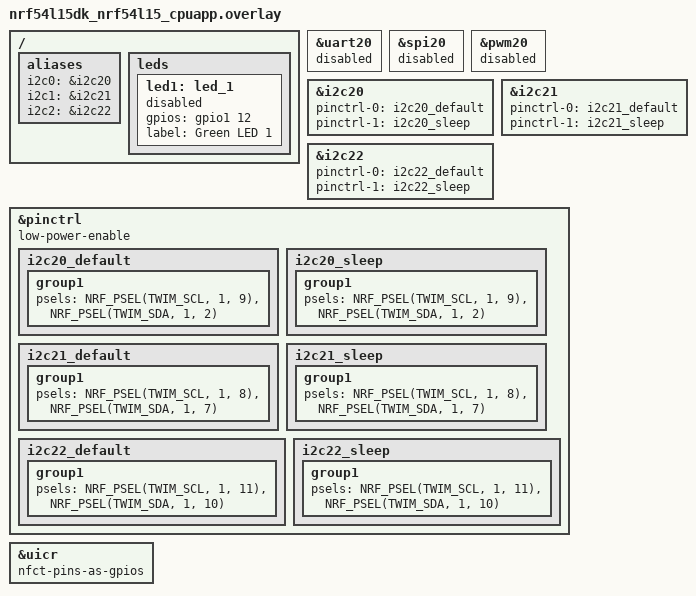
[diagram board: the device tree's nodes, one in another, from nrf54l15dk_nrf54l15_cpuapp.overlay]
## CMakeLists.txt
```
cmake_minimum_required(VERSION 3.20.0)
find_package(Zephyr REQUIRED HINTS $ENV{ZEPHYR_BASE})
project(Nadi_Pulse_AV)

target_sources(app PRIVATE src/main.c)
```

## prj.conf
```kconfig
CONFIG_BT=y
CONFIG_BT_PERIPHERAL=y
CONFIG_BT_DEVICE_NAME="NADI_PULSE_AV"
CONFIG_BT_GATT_CLIENT=y
CONFIG_BT_USER_DATA_LEN_UPDATE=y
CONFIG_BT_CTLR_DATA_LENGTH_MAX=251
CONFIG_BT_BUF_ACL_RX_SIZE=251
CONFIG_BT_BUF_ACL_TX_SIZE=251
CONFIG_BT_L2CAP_TX_MTU=247
CONFIG_BT_CTLR_PHY_2M=y
CONFIG_SYSTEM_WORKQUEUE_STACK_SIZE=2048
CONFIG_MAIN_STACK_SIZE=2048
CONFIG_BT_RX_STACK_SIZE=2048
CONFIG_LOG=y
CONFIG_SERIAL=y
CONFIG_PRINTK=y
CONFIG_I2C=y
CONFIG_SENSOR=y
CONFIG_NRF_FUEL_GAUGE=y
CONFIG_NRF_FUEL_GAUGE_VARIANT_SECONDARY_CELL=y
CONFIG_BT_DATA_LEN_UPDATE=y
CONFIG_BT_USER_PHY_UPDATE=y
CONFIG_BT_PHY_UPDATE=y
CONFIG_BT_AUTO_PHY_UPDATE=n
CONFIG_BT_BUF_CMD_TX_COUNT=10
CONFIG_BT_CTLR_PHY_CODED=y
CONFIG_MCUBOOT_IMGTOOL_SIGN_VERSION="0.1.0"
CONFIG_NCS_SAMPLE_MCUMGR_BT_OTA_DFU=y
```

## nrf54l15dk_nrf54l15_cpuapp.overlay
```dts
/ {
   aliases {
    i2c0 = &i2c20;
	i2c1 = &i2c21;
	i2c2 = &i2c22;
   };
   leds {
	led1: led_1 {
			status="disabled";
			gpios = <&gpio1 12 GPIO_ACTIVE_HIGH>;
			label = "Green LED 1";
		};
   };
};
&uart20 { status = "disabled"; };
&spi20 { status = "disabled"; };
&pwm20 {status="disabled";};
&i2c20 {
    status="okay";
    pinctrl-0 = <&i2c20_default>;
	pinctrl-1 = <&i2c20_sleep>;
	pinctrl-names = "default", "sleep";
};

&i2c21 {
    status="okay";
    pinctrl-0 = <&i2c21_default>;
	pinctrl-1 = <&i2c21_sleep>;
	pinctrl-names = "default", "sleep";
};

&i2c22 {
    status="okay";
    pinctrl-0 = <&i2c22_default>;
	pinctrl-1 = <&i2c22_sleep>;
	pinctrl-names = "default", "sleep";
};


&pinctrl {

	i2c20_default: i2c20_default {
		group1 {
			psels = <NRF_PSEL(TWIM_SCL, 1, 9)>, <NRF_PSEL(TWIM_SDA, 1, 2)>;
		};
	};

	i2c20_sleep: i2c20_sleep {
		group1 {
			psels = <NRF_PSEL(TWIM_SCL, 1, 9)>, <NRF_PSEL(TWIM_SDA, 1, 2)>;
		};
	};

	i2c21_default: i2c21_default {
		group1 {
			psels = <NRF_PSEL(TWIM_SCL, 1, 8)>, <NRF_PSEL(TWIM_SDA, 1, 7)>;
		};
	};

	i2c21_sleep: i2c21_sleep {
		group1 {
			psels = <NRF_PSEL(TWIM_SCL, 1, 8)>, <NRF_PSEL(TWIM_SDA, 1, 7)>;
		};
	};

	i2c22_default: i2c22_default {
		group1 {
			psels = <NRF_PSEL(TWIM_SCL, 1, 11)>, <NRF_PSEL(TWIM_SDA, 1, 10)>;
		};
	};

	i2c22_sleep: i2c22_sleep {
		group1 {
			psels = <NRF_PSEL(TWIM_SCL, 1, 11)>, <NRF_PSEL(TWIM_SDA, 1, 10)>;
		};
	};

	low-power-enable;
	
};

&uicr {
	nfct-pins-as-gpios;
};
```

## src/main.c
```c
#include <zephyr/kernel.h>
#include <zephyr/device.h>
#include <zephyr/drivers/i2c.h>
#include <zephyr/bluetooth/bluetooth.h>
#include "fuel_gauge.h"
#include "ble.h"

// MAX30102 Register map
#define I2C_DEV_LABEL0 DT_ALIAS(i2c0)
#define I2C_DEV_LABEL1 DT_ALIAS(i2c1)
#define I2C_DEV_LABEL2 DT_ALIAS(i2c2)
#define MAX30102_I2C_ADDR 0x57
#define REG_INTR_STATUS_1 0x00
#define REG_INTR_ENABLE_1 0x02
#define REG_FIFO_WR_PTR 0x04
#define REG_OVF_COUNTER 0x05
#define REG_FIFO_RD_PTR 0x06
#define REG_FIFO_DATA 0x07
#define REG_FIFO_CONFIG 0x08
#define REG_MODE_CONFIG 0x09
#define REG_SPO2_CONFIG 0x0A
#define REG_LED1_PA 0x0C
#define REG_LED2_PA 0x0D


const struct device *i2c_dev0, *i2c_dev1, *i2c_dev2;
/* Nadi pulse Data */
uint8_t x;
uint8_t y = 0;
uint32_t red0, ir0;
uint32_t red1, ir1;
uint32_t red2, ir2;
int32_t sub_red_0 = 0, sub_ir_0 = 0;
int32_t sub_red_1 = 0, sub_ir_1 = 0;
int32_t sub_red_2 = 0, sub_ir_2 = 0;
int32_t prev_red_0 = 0, prev_ir_0 = 0;
int32_t prev_red_1 = 0, prev_ir_1 = 0;
int32_t prev_red_2 = 0, prev_ir_2 = 0;

static int write_reg0(uint8_t reg, uint8_t value)
{
    uint8_t buf[2] = {reg, value};
    return i2c_write(i2c_dev0, buf, sizeof(buf), MAX30102_I2C_ADDR);
}
static int read_reg0(uint8_t reg, uint8_t *value)
{
    return i2c_write_read(i2c_dev0, MAX30102_I2C_ADDR, &reg, 1, value, 1);
}

static int read_fifo0(uint32_t *red, uint32_t *ir)
{
    uint8_t reg = REG_FIFO_DATA;
    uint8_t data[6];

    i2c_write_read(i2c_dev0, MAX30102_I2C_ADDR, &reg, 1, data, 6);
    red0 = ((uint32_t)data[0] << 16) |
           ((uint32_t)data[1] << 8) |
           data[2];
    ir0 = ((uint32_t)data[3] << 16) |
          ((uint32_t)data[4] << 8) | data[5];

    sub_red_0 = (red0 - prev_red_0);
    sub_ir_0 = (ir0 - prev_ir_0);

    if (sub_red_0 > 1000)
    {
        sub_red_0 = 1000;
    }
    else if (sub_red_0 < -1000)
    {
        sub_red_0 = -1000;
    }
    if (sub_ir_0 > 1000)
    {
        sub_ir_0 = 1000;
    }
    else if (sub_ir_0 < -1000)
    {
        sub_ir_0 = -1000;
    }
    prev_red_0 = red0;
    prev_ir_0 = ir0;
    return 0;
}

static int write_reg1(uint8_t reg, uint8_t value)
{
    uint8_t buf[2] = {reg, value};
    return i2c_write(i2c_dev1, buf, sizeof(buf), MAX30102_I2C_ADDR);
}
static int read_reg1(uint8_t reg, uint8_t *value)
{
    return i2c_write_read(i2c_dev1, MAX30102_I2C_ADDR, &reg, 1, value, 1);
}

// Read 6 bytes from FIFO (3 for RED, 3 for IR)
static int read_fifo1(uint32_t *red, uint32_t *ir)
{
    uint8_t reg = REG_FIFO_DATA;
    uint8_t data[6];

    i2c_write_read(i2c_dev1, MAX30102_I2C_ADDR, &reg, 1, data, 6);
    red1 = ((uint32_t)data[0] << 16) |
           ((uint32_t)data[1] << 8) |
           data[2];
    ir1 = ((uint32_t)data[3] << 16) |
          ((uint32_t)data[4] << 8) |
          data[5];

    sub_red_1 = (red1 - prev_red_1);
    sub_ir_1 = (ir1 - prev_ir_1);

    if (sub_red_1 > 1000)
    {
        sub_red_1 = 1000;
    }
    else if (sub_red_1 < -1000)
    {
        sub_red_1 = -1000;
    }
    if (sub_ir_1 > 1000)
    {
        sub_ir_1 = 1000;
    }
    else if (sub_ir_1 < -1000)
    {
        sub_ir_1 = -1000;
    }
    prev_red_1 = red1;
    prev_ir_1 = ir1;
    return 0;
}

static int write_reg2(uint8_t reg, uint8_t value)
{
    uint8_t buf[2] = {reg, value};
    return i2c_write(i2c_dev2, buf, sizeof(buf), MAX30102_I2C_ADDR);
}

static int read_reg2(uint8_t reg, uint8_t *value)
{
    return i2c_write_read(i2c_dev2, MAX30102_I2C_ADDR, &reg, 1, value, 1);
}

static int read_fifo2(uint32_t *red, uint32_t *ir)
{
    uint8_t reg = REG_FIFO_DATA;
    uint8_t data[6];

    i2c_write_read(i2c_dev2, MAX30102_I2C_ADDR, &reg, 1, data, 6);
    red2 = ((uint32_t)data[0] << 16) |
           ((uint32_t)data[1] << 8) |
           data[2];
    ir2 = ((uint32_t)data[3] << 16) |
          ((uint32_t)data[4] << 8) |
          data[5];

    sub_red_2 = (red2 - prev_red_2);
    sub_ir_2 = (ir2 - prev_ir_2);

    if (sub_red_2 > 1000)
    {
        sub_red_2 = 1000;
    }
    else if (sub_red_2 < -1000)
    {
        sub_red_2 = -1000;
    }
    if (sub_ir_2 > 1000)
    {
        sub_ir_2 = 1000;
    }
    else if (sub_ir_2 < -1000)
    {
        sub_ir_2 = -1000;
    }

    prev_red_2 = red2;
    prev_ir_2 = ir2;

    return 0;
}

static void max30102_init0(void)
{
    write_reg0(REG_MODE_CONFIG, 0x40);
    k_msleep(100);
    write_reg0(REG_FIFO_WR_PTR, 0x00);
    write_reg0(REG_OVF_COUNTER, 0x00);
    write_reg0(REG_FIFO_RD_PTR, 0x00);
    write_reg0(REG_FIFO_CONFIG, 0x4F);
    write_reg0(REG_MODE_CONFIG, 0x03);
   /*
    [7:5] = 0b100 = 400 Hz
    [4:2] = 0b01  = 118 us pulse
    [1:0] = 0b11  = 18-bit ADC*/
    write_reg0(REG_SPO2_CONFIG, 0x3b);
    write_reg0(REG_LED2_PA, 0x3f);
    write_reg0(REG_LED1_PA, 0x4f);
    write_reg0(0x11, 0x21);
    write_reg0(0x12, 0x00);
    printk("MAX30102_0 initialized");
}

static void max30102_init1(void)
{
    write_reg1(REG_MODE_CONFIG, 0x40);
    k_msleep(100);
    write_reg1(REG_FIFO_WR_PTR, 0x00);
    write_reg1(REG_OVF_COUNTER, 0x00);
    write_reg1(REG_FIFO_RD_PTR, 0x00);
    write_reg1(REG_FIFO_CONFIG, 0x4F);
    write_reg1(REG_MODE_CONFIG, 0x03);
    write_reg1(REG_SPO2_CONFIG, 0x3b);
    write_reg1(REG_LED2_PA, 0x3f);
    write_reg1(REG_LED1_PA, 0x4f);
    write_reg1(0x11, 0x21);
    write_reg1(0x12, 0x00);
    printk("MAX30102_1 initialized");
}

static void max30102_init2(void)
{
    write_reg2(REG_MODE_CONFIG, 0x40);
    k_msleep(100);
    write_reg2(REG_FIFO_WR_PTR, 0x00);
    write_reg2(REG_OVF_COUNTER, 0x00);
    write_reg2(REG_FIFO_RD_PTR, 0x00);
    write_reg2(REG_FIFO_CONFIG, 0x4F);
    write_reg2(REG_MODE_CONFIG, 0x03);
    write_reg2(REG_SPO2_CONFIG, 0x3b);
    write_reg2(REG_LED2_PA, 0x3f);
    write_reg2(REG_LED1_PA, 0x4f);
    write_reg2(0x11, 0x21);
    write_reg2(0x12, 0x00);
    printk("MAX30102_2 initialized");
}

static void max30102_deinit0(void)
{
    write_reg0(REG_MODE_CONFIG, 0x80);
    write_reg0(REG_LED1_PA, 0x00);
    write_reg0(REG_LED2_PA, 0x00);
    write_reg0(REG_FIFO_WR_PTR, 0x00);
    write_reg0(REG_OVF_COUNTER, 0x00);
    write_reg0(REG_FIFO_RD_PTR, 0x00);
}

static void max30102_deinit1(void)
{
    write_reg1(REG_MODE_CONFIG, 0x80);
    write_reg1(REG_LED1_PA, 0x00);
    write_reg1(REG_LED2_PA, 0x00);
    write_reg1(REG_FIFO_WR_PTR, 0x00);
    write_reg1(REG_OVF_COUNTER, 0x00);
    write_reg1(REG_FIFO_RD_PTR, 0x00);
}

static void max30102_deinit2(void)
{
    write_reg2(REG_MODE_CONFIG, 0x80);
    write_reg2(REG_LED1_PA, 0x00);
    write_reg2(REG_LED2_PA, 0x00);
    write_reg2(REG_FIFO_WR_PTR, 0x00);
    write_reg2(REG_OVF_COUNTER, 0x00);
    write_reg2(REG_FIFO_RD_PTR, 0x00);
}

void combine_data()
{
    memset(data, 0, sizeof(data));
    snprintf(data, sizeof(data), "%d,%d,%d,%d,%d,%d,", sub_red_0, sub_ir_0, sub_red_1, sub_ir_1, sub_red_2, sub_ir_2);
    if (ble_connected && notify_enabled)
    {
        notify_data();
    }
}
int main(void)
{
    i2c_dev0 = DEVICE_DT_GET(I2C_DEV_LABEL0);
    if (!i2c_dev0)
    {
        printk("I2C: device not found using alias,\n");
    }
    if (!i2c_dev0)
    {
        printk("I2C: device not found\n");
    }

    i2c_dev1 = DEVICE_DT_GET(I2C_DEV_LABEL1);
    if (!i2c_dev1)
    {
        printk("I2C: device not found using alias,\n");
    }
    if (!i2c_dev1)
    {
        printk("I2C: device not found\n");
    }
    i2c_dev2 = DEVICE_DT_GET(I2C_DEV_LABEL2);
    if (!i2c_dev2)
    {
        printk("I2C: device not found using alias,\n");
    }
    if (!i2c_dev2)
    {
        printk("I2C: device not found\n");
    }
    ble_init();
    start_advertising();

    rx_buf[0] = 'd';
    while (1)
    {
        int ret = 0;
        if (sensor_status == 1)
        {
            if (rx_buf[0] == 'c') /* VAT */
            {
                max30102_init0();
                max30102_deinit1();
                max30102_deinit2();
                sensor_status = 0;
            }
            else if (rx_buf[0] == 'b') /* PIT */
            {
                max30102_deinit0();
                max30102_init1();
                max30102_deinit2();
                sensor_status = 0;
            }
            else if (rx_buf[0] == 'a') /* KAF */
            {
                max30102_deinit0();
                max30102_deinit1();
                max30102_init2();
                sensor_status = 0;
            }
            else if (rx_buf[0] == 'd')
            {
                max30102_init0();
                max30102_init1();
                max30102_init2();
                sensor_status = 0;
            }
            else if (rx_buf[0] == 'e')
            {
                max30102_deinit0();
                max30102_deinit1();
                max30102_deinit2();
                sensor_status = 0;
            }
            else
            {
                printk("Invalid Command\n");
            }
            sensor_status = 0;
        }
        if (rx_buf[0] == 'c' || rx_buf[0] == 'd')
            ret = read_fifo0(&red0, &ir0);

        if (rx_buf[0] == 'b' || rx_buf[0] == 'd')
            ret = read_fifo1(&red1, &ir1);

        if (rx_buf[0] == 'a' || rx_buf[0] == 'd')
            ret = read_fifo2(&red2, &ir2);

        combine_data();
        k_msleep(10);
    }
    return 0;
}
```

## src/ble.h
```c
#include <zephyr/kernel.h>
#include <zephyr/bluetooth/bluetooth.h>
#include <zephyr/bluetooth/conn.h>
#include <zephyr/bluetooth/gatt.h>
#include <zephyr/bluetooth/uuid.h>
#include <zephyr/sys/printk.h>


#define SDC_HCI_VS_LL_HANDLE_TYPE_ADV 0x00
#define BT_UUID_CUSTOM_SERVICE_VAL \
BT_UUID_128_ENCODE(0x12345678, 0x1234, 0x5678, 0x9abc, 0xdef012345678)
#define BT_UUID_CUSTOM_CHAR_VAL \
BT_UUID_128_ENCODE(0x12345678, 0x1234, 0x5678, 0x9abc, 0xdef012345679)

static struct bt_uuid_128 custom_service_uuid = BT_UUID_INIT_128(BT_UUID_CUSTOM_SERVICE_VAL);
static struct bt_uuid_128 custom_char_uuid = BT_UUID_INIT_128(BT_UUID_CUSTOM_CHAR_VAL);
static struct bt_conn *default_conn;
static int sensor_status = 0;
static bool ble_connected = false;
uint8_t r;
int8_t led_status = 0; 
uint8_t start_adv =0;
static uint8_t data[50]="";
static bool notify_enabled = false;

static void ccc_cfg_changed(const struct bt_gatt_attr *attr, uint16_t value)
{
	notify_enabled = (value == BT_GATT_CCC_NOTIFY);
	printk("Notifications %s\n", notify_enabled ? "enabled" : "disabled");
}
static ssize_t read_data(struct bt_conn *conn,
			    const struct bt_gatt_attr *attr,
			    void *buf, uint16_t len, uint16_t offset)
{
	return bt_gatt_attr_read(conn, attr, buf, len, offset, &data, sizeof(data));
}
static uint8_t rx_buf[20];
static ssize_t write_my_char(struct bt_conn *conn,
                             const struct bt_gatt_attr *attr,
                             const void *buf, uint16_t len,
                             uint16_t offset, uint8_t flags)
{
    uint16_t copy_len = MIN(len, sizeof(rx_buf) - 1);
    memcpy(rx_buf, buf, copy_len);
    rx_buf[copy_len] = '\0';
    if (len == 0) {
        return 0;
    }
    sensor_status=1;
    return BT_GATT_ERR(BT_ATT_ERR_INVALID_ATTRIBUTE_LEN);
}
BT_GATT_SERVICE_DEFINE(custom_svc,
	BT_GATT_PRIMARY_SERVICE(&custom_service_uuid),
	BT_GATT_CHARACTERISTIC(&custom_char_uuid.uuid,
			       BT_GATT_CHRC_READ | BT_GATT_CHRC_WRITE |BT_GATT_CHRC_NOTIFY,
			       BT_GATT_PERM_READ | BT_GATT_PERM_WRITE,
			       read_data, write_my_char, &data),
	BT_GATT_CCC(ccc_cfg_changed, BT_GATT_PERM_READ | BT_GATT_PERM_WRITE)
);

static void connected(struct bt_conn *conn, uint8_t err);
static void disconnected(struct bt_conn *conn, uint8_t reason);
static struct bt_conn_cb conn_callbacks = {
    .connected = connected,
    .disconnected = disconnected,
};

static void connected(struct bt_conn *conn, uint8_t err)
{
    if (err) {
        printk("Connection failed (err 0x%02x)\n", err);
    } else {
        char addr[BT_ADDR_LE_STR_LEN];
        bt_addr_le_to_str(bt_conn_get_dst(conn), addr, sizeof(addr));
        printk("Connected to: %s\n", addr);
		default_conn = bt_conn_ref(conn);
        ble_connected=true;
        led_status=2;
    }
}
static void disconnected(struct bt_conn *conn, uint8_t reason)
{
    char addr[BT_ADDR_LE_STR_LEN];
    bt_addr_le_to_str(bt_conn_get_dst(conn), addr, sizeof(addr));
    printk("Disconnected from: %s (reason 0x%02x)\n", addr, reason);
    r=reason;
    ble_connected=false;
    led_status=0;
    start_adv=1;
     if (default_conn) {
        bt_conn_unref(default_conn);
        default_conn = NULL;
     }
}
int8_t ble_init(void) {
    int err;
    err = bt_enable(NULL);
    if (err) {
        printk("Bluetooth init failed (err %d)\n", err);
        return err;
    }
    printk("Bluetooth initialized\n");
    bt_conn_cb_register(&conn_callbacks);
    return 0;
}
int8_t ble_deinit(void) {
    int err;
    if (default_conn) {
        err = bt_conn_disconnect(default_conn, BT_HCI_ERR_REMOTE_USER_TERM_CONN);
        if (err) {
            printk("Disconnection failed (err %d)\n", err);
            return err;
        }
        bt_conn_unref(default_conn);
        default_conn = NULL;
        printk("Disconnection initiated\n");
    }
    err = bt_disable();
    if (err) {
        printk("Bluetooth disable failed (err %d)\n", err);
        return err;
    }
    printk("Bluetooth disabled\n");
    led_status=0;
    return 0;
}   

int8_t start_advertising(void) {
    int err;
    struct bt_le_adv_param *adv_params =
        BT_LE_ADV_PARAM(BT_LE_ADV_OPT_CONNECTABLE | BT_LE_ADV_OPT_USE_NAME,
                        BT_GAP_ADV_FAST_INT_MIN_2,
                        BT_GAP_ADV_FAST_INT_MAX_2,
                        NULL);

    const struct bt_data ad[] = {
        BT_DATA_BYTES(BT_DATA_FLAGS, (BT_LE_AD_GENERAL | BT_LE_AD_NO_BREDR)),
        BT_DATA_BYTES(BT_DATA_UUID128_ALL, BT_UUID_CUSTOM_SERVICE_VAL),
    };

    err = bt_le_adv_start(adv_params, ad, ARRAY_SIZE(ad), NULL, 0);
    if (err) {
        printk("Advertising failed to start (err %d)\n", err);
        return err;
    }
    printk("Advertising successfully started\n");
    led_status=1;
    return 0;
}   
int8_t stop_advertising(void) {
    int err;

    err = bt_le_adv_stop();
    if (err) {
        printk("Failed to stop advertising (err %d)\n", err);
        return err;
    }
    printk("Advertising successfully stopped\n");
    led_status=0;
    return 0;
}
int8_t disconnect(void) {
    int err;
    if (default_conn) {
        err = bt_conn_disconnect(default_conn, BT_HCI_ERR_REMOTE_USER_TERM_CONN);
        if (err) {
            printk("Disconnection failed (err %d)\n", err);
            return err;
        }
        bt_conn_unref(default_conn);
        default_conn = NULL;
        printk("Disconnection initiated\n");
    } else {
        printk("No active connection to disconnect\n");
    }
    led_status=0;
    return 0;
}
int8_t notify_data(void) {
    int err;
    if (!default_conn) {
        printk("No active connection. Cannot send notification.\n");
        return -ENOTCONN;
    }
    if (!notify_enabled) {
        printk("Notifications not enabled by the client.\n");
        return -EACCES;
    }

    err = bt_gatt_notify(default_conn, &custom_svc.attrs[1], &data, sizeof(data));
    if (err) {
        printk("Notification failed (err %d)\n", err);
        return err;
    }
    printk("Notification sent successfully\n");
    return 0;
}
```
